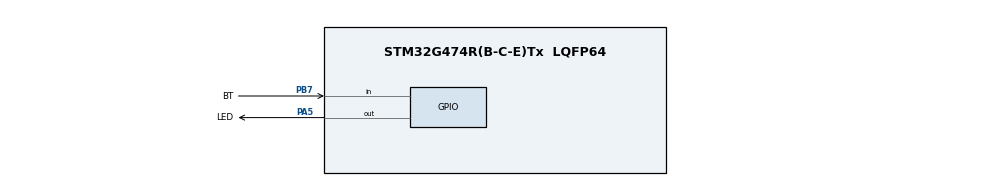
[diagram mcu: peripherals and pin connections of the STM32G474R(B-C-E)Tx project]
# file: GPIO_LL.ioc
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Mcu.Family=STM32G4
Mcu.Name=STM32G474R(B-C-E)Tx
Mcu.Package=LQFP64
NVIC.PriorityGroup=NVIC_PRIORITYGROUP_4
PA13.Mode=Serial_Wire
PA13.Signal=SYS_JTMS-SWDIO
PA14.Mode=Serial_Wire
PA14.Signal=SYS_JTCK-SWCLK
PA5.GPIO_Label=LED
PA5.Signal=GPIO_Output
PB7.GPIO_Label=BT
PB7.Signal=GPIO_Input
ProjectManager.HeapSize=0x200
ProjectManager.StackSize=0x400
ProjectManager.TargetToolchain=Makefile
RCC.ADC12Freq_Value=170000000
RCC.ADC345Freq_Value=170000000
RCC.AHBFreq_Value=170000000
RCC.APB1Freq_Value=170000000
RCC.APB1TimFreq_Value=170000000
RCC.APB2Freq_Value=170000000
RCC.APB2TimFreq_Value=170000000
RCC.CortexFreq_Value=170000000
RCC.EXTERNAL_CLOCK_VALUE=12288000
RCC.HCLKFreq_Value=170000000
RCC.HSE_VALUE=8000000
RCC.HSI48_VALUE=48000000
RCC.HSI_VALUE=16000000
RCC.LSE_VALUE=32768
RCC.PLLM=RCC_PLLM_DIV4
RCC.PLLN=85
RCC.SYSCLKFreq_VALUE=170000000
RCC.SYSCLKSource=RCC_SYSCLKSOURCE_PLLCLK
RCC.USBFreq_Value=170000000
RCC.VCOOutputFreq_Value=340000000
VP_SYS_VS_DBSignals.Mode=DisableDeadBatterySignals
board=custom

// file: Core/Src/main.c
/* USER CODE BEGIN Header */
/**
  ******************************************************************************
  * @file           : main.c
  * @brief          : Main program body
  ******************************************************************************
  * @attention
  *
  * Copyright (c) 2024 STMicroelectronics.
  * All rights reserved.
  *
  * This software is licensed under terms that can be found in the LICENSE file
  * in the root directory of this software component.
  * If no LICENSE file comes with this software, it is provided AS-IS.
  *
  ******************************************************************************
  */
/* USER CODE END Header */
#include "main.h"
#include "gpio.h"

/* USER CODE BEGIN Includes */
#include "stm32g4xx_ll_gpio.h"

/* USER CODE END Includes */

/* USER CODE BEGIN PD */
#define LED_Init_without_gpio
// #define LED_Init_with_gpio_LL

/* USER CODE END PD */

void SystemClock_Config(void);
/* USER CODE BEGIN PFP */
#ifdef LED_Init_with_gpio_LL
void LED_Init(void);
void LED_Toggle(void);

#endif // DEBUG
#ifdef LED_Init_without_gpio
#define LED2_GPIO_CLK_ENABLE()             LL_AHB2_GRP1_EnableClock(LL_AHB2_GRP1_PERIPH_GPIOA)
void     Configure_GPIO(void);
#endif

/* USER CODE END PFP */

int main(void)
{

  /* MCU Configuration--------------------------------------------------------*/

  /* Reset of all peripherals, Initializes the Flash interface and the Systick. */
  LL_APB2_GRP1_EnableClock(LL_APB2_GRP1_PERIPH_SYSCFG);
  LL_APB1_GRP1_EnableClock(LL_APB1_GRP1_PERIPH_PWR);

  /* System interrupt init*/
  NVIC_SetPriorityGrouping(NVIC_PRIORITYGROUP_4);

  /* SysTick_IRQn interrupt configuration */
  NVIC_SetPriority(SysTick_IRQn, NVIC_EncodePriority(NVIC_GetPriorityGrouping(),15, 0));

  /** Disable the internal Pull-Up in Dead Battery pins of UCPD peripheral
  */
  LL_PWR_DisableUCPDDeadBattery();

  /* Configure the system clock */
  SystemClock_Config();

  /* Initialize all configured peripherals */
  #ifdef LED_Init_with_gpio_LL
  MX_GPIO_Init();
  #endif
  /* USER CODE BEGIN 2 */
  #ifdef LED_Init_with_gpio_LL
  LED_Init();
  #endif
  #ifdef LED_Init_without_gpio
  Configure_GPIO();
  #endif
  /* USER CODE END 2 */

  /* Infinite loop */
  while (1)
  {

    /* USER CODE BEGIN 3 */
    /* Toggle LED */
      #ifdef LED_Init_with_gpio_LL
        LED_Toggle();
         /* Delay (you can add your own delay function here if needed) */
        for (volatile int i = 0; i < 1000000; i++) {}
      #endif
      #ifdef LED_Init_without_gpio
        LL_GPIO_TogglePin(LED_GPIO_Port, LED_Pin);

        /* Insert delay 250 ms */
        LL_mDelay(250);
      #endif
  }
  /* USER CODE END 3 */
}

void SystemClock_Config(void)
{
  LL_FLASH_SetLatency(LL_FLASH_LATENCY_4);
  while(LL_FLASH_GetLatency() != LL_FLASH_LATENCY_4)
  {
  }
  LL_PWR_EnableRange1BoostMode();
  LL_RCC_HSI_Enable();
   /* Wait till HSI is ready */
  while(LL_RCC_HSI_IsReady() != 1)
  {
  }

  LL_RCC_HSI_SetCalibTrimming(64);
  LL_RCC_PLL_ConfigDomain_SYS(LL_RCC_PLLSOURCE_HSI, LL_RCC_PLLM_DIV_4, 85, LL_RCC_PLLR_DIV_2);
  LL_RCC_PLL_EnableDomain_SYS();
  LL_RCC_PLL_Enable();
   /* Wait till PLL is ready */
  while(LL_RCC_PLL_IsReady() != 1)
  {
  }

  LL_RCC_SetSysClkSource(LL_RCC_SYS_CLKSOURCE_PLL);
  LL_RCC_SetAHBPrescaler(LL_RCC_SYSCLK_DIV_2);
   /* Wait till System clock is ready */
  while(LL_RCC_GetSysClkSource() != LL_RCC_SYS_CLKSOURCE_STATUS_PLL)
  {
  }

  /* Insure 1us transition state at intermediate medium speed clock*/
  for (__IO uint32_t i = (170 >> 1); i !=0; i--);

  /* Set AHB prescaler*/
  LL_RCC_SetAHBPrescaler(LL_RCC_SYSCLK_DIV_1);
  LL_RCC_SetAPB1Prescaler(LL_RCC_APB1_DIV_1);
  LL_RCC_SetAPB2Prescaler(LL_RCC_APB2_DIV_1);

  LL_Init1msTick(170000000);

  LL_SetSystemCoreClock(170000000);
}

/* USER CODE BEGIN 4 */
#ifdef LED_Init_with_gpio_LL
void LED_Init(void)
{
    LL_GPIO_InitTypeDef GPIO_InitStruct = {0};

    /* GPIO Ports Clock Enable */
    LL_APB2_GRP1_EnableClock(LL_AHB2_GRP1_PERIPH_GPIOA);

    /*Configure GPIO pin Output Level */
    LL_GPIO_ResetOutputPin(LED_GPIO_Port, LED_Pin);

    /*Configure GPIO pin : LED_Pin */
    GPIO_InitStruct.Pin = LED_Pin;
    GPIO_InitStruct.Mode = LL_GPIO_MODE_OUTPUT;
    GPIO_InitStruct.Speed = LL_GPIO_SPEED_FREQ_HIGH;
    GPIO_InitStruct.OutputType = LL_GPIO_OUTPUT_PUSHPULL;
    GPIO_InitStruct.Pull = LL_GPIO_PULL_NO;
    LL_GPIO_Init(LED_GPIO_Port, &GPIO_InitStruct);
}

void LED_Toggle(void)
{
    LL_GPIO_TogglePin(LED_GPIO_Port, LED_Pin);
}
#endif // DEBUG

#ifdef LED_Init_without_gpio
void Configure_GPIO(void)
{
  /* Enable the LED2 Clock */
  LED2_GPIO_CLK_ENABLE();

  /* Configure IO */
  LL_GPIO_SetPinMode(LED_GPIO_Port, LED_Pin, LL_GPIO_MODE_OUTPUT);
  /* Reset value is LL_GPIO_OUTPUT_PUSHPULL */
  //LL_GPIO_SetPinOutputType(LED2_GPIO_PORT, LED2_PIN, LL_GPIO_OUTPUT_PUSHPULL);
  /* Reset value is LL_GPIO_SPEED_FREQ_LOW */
  //LL_GPIO_SetPinSpeed(LED2_GPIO_PORT, LED2_PIN, LL_GPIO_SPEED_FREQ_LOW);
  /* Reset value is LL_GPIO_PULL_NO */
  //LL_GPIO_SetPinPull(LED2_GPIO_PORT, LED2_PIN, LL_GPIO_PULL_NO);
}
#endif

/* USER CODE END 4 */

void Error_Handler(void)
{
  __disable_irq();
  while (1)
  {
  }
}
